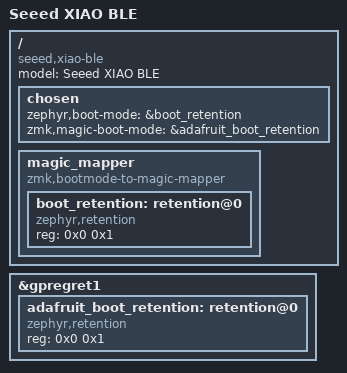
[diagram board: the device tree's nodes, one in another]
/*
 * Copyright (c) 2022-2023 Marcin Niestroj
 *
 * SPDX-License-Identifier: Apache-2.0
 */

/dts-v1/;
#include "xiao_ble_common.dtsi"
#include <common/nordic/nrf52840_uf2_boot_mode.dtsi>

/ {
	model = "Seeed XIAO BLE";
	compatible = "seeed,xiao-ble";

    chosen {
        zephyr,boot-mode = &boot_retention;
        zmk,magic-boot-mode = &adafruit_boot_retention;
    };

    magic_mapper {
        compatible = "zmk,bootmode-to-magic-mapper";
        status = "okay";

        #address-cells = <1>;
        #size-cells = <1>;

        boot_retention: retention@0 {
            compatible = "zephyr,retention";
            status = "okay";
            reg = <0x0 0x1>;
        };
    };
};

&gpregret1 {
    adafruit_boot_retention: retention@0 {
        compatible = "zephyr,retention";
        status = "okay";
        reg = <0x0 0x1>;
    };
};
